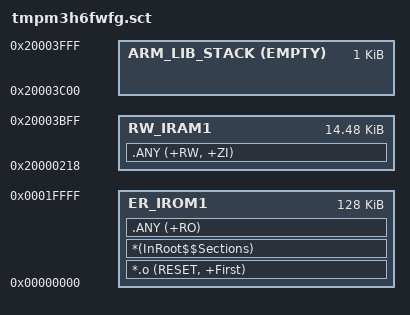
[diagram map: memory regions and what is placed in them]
#! armcc -E

;;  TMPM3H6FWFG scatter file

;;  Vector table starts at 0
;;    Initial SP == |Image$$ARM_LIB_STACK$$ZI$$Limit| (for two region model)
;;               or |Image$$ARM_LIB_STACKHEAP$$ZI$$Limit| (for one region model)
;;    Initial PC == &__main (with LSB set to indicate Thumb)
;;    These two values are provided by the library
;;    Other vectors must be provided by the user
;;  Code starts after the last possible vector
;;  Data starts at 0x20000000
;;    Heap is positioned by ARM_LIB_HEAB (this is the heap managed by the ARM libraries)
;;    Stack is positioned by ARM_LIB_STACK (library will use this to set SP - see above)

;; Compatible with ISSM model

#if !defined(MBED_BOOT_STACK_SIZE)
  #define MBED_BOOT_STACK_SIZE 0x400
#endif

#define Stack_Size MBED_BOOT_STACK_SIZE

LR_IROM1 0x00000000 0x20000
{
  ER_IROM1 0x00000000 0x20000
  {
    *.o (RESET, +First)
    *(InRoot$$Sections)
    .ANY (+RO)
  }
  ; 8_byte_aligned(117 + 16 vect * 4 bytes) =  8_byte_aligned(0x214) = 0x218
  RW_IRAM1 (0x20000000 + 0x218) (0x4000 - 0x218 - Stack_Size)
  {
    .ANY (+RW, +ZI)
  }

  ARM_LIB_STACK (0x20000000+0x4000) EMPTY -Stack_Size { ; stack
  }
}
